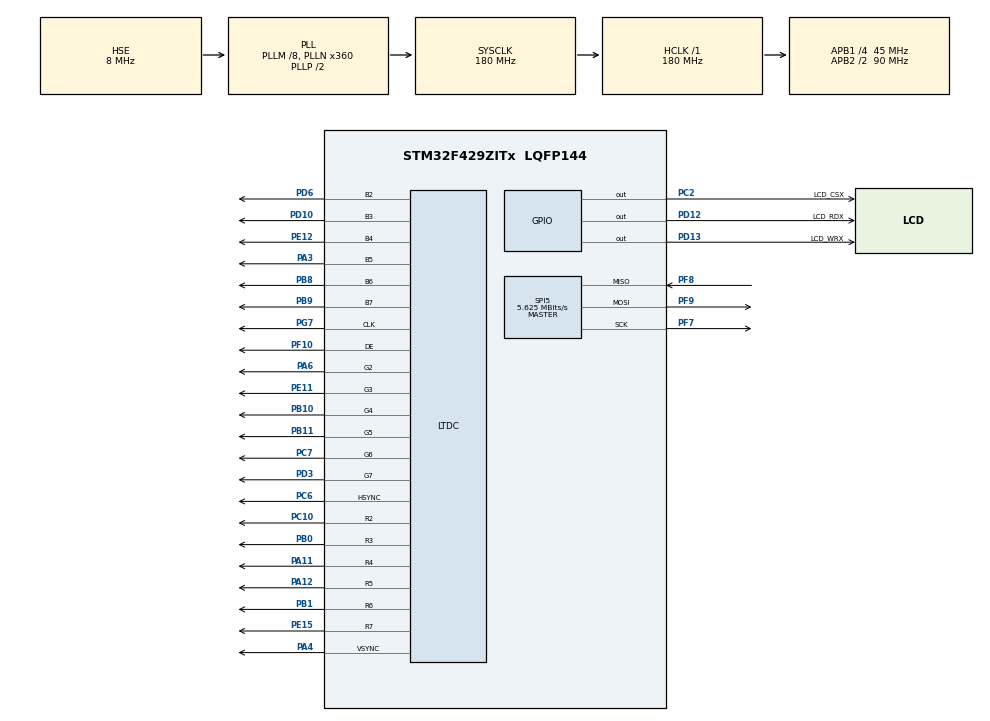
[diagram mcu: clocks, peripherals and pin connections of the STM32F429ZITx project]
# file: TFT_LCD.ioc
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LTDC.ActiveH=320
LTDC.ActiveW=240
LTDC.Alpha_L0=255
LTDC.HBP=20
LTDC.HFP=10
LTDC.HSync=10
LTDC.ImageHeight_L0=320
LTDC.ImageWidth_L0=240
LTDC.Layers=0
LTDC.PixelFormat_L0=LTDC_PIXEL_FORMAT_RGB888
LTDC.VFP=4
LTDC.VSync=2
LTDC.WindowX1_L0=240
LTDC.WindowY1_L0=320
Mcu.Family=STM32F4
Mcu.Name=STM32F429ZITx
Mcu.Package=LQFP144
NVIC.PriorityGroup=NVIC_PRIORITYGROUP_4
PA11.GPIO_Speed=GPIO_SPEED_FREQ_HIGH
PA11.Mode=RGB666
PA11.Signal=LTDC_R4
PA12.GPIO_Speed=GPIO_SPEED_FREQ_HIGH
PA12.Mode=RGB666
PA12.Signal=LTDC_R5
PA13.Mode=Serial_Wire
PA13.Signal=SYS_JTMS-SWDIO
PA14.Mode=Serial_Wire
PA14.Signal=SYS_JTCK-SWCLK
PA3.GPIO_Speed=GPIO_SPEED_FREQ_HIGH
PA3.Mode=RGB666
PA3.Signal=LTDC_B5
PA4.GPIO_Speed=GPIO_SPEED_FREQ_HIGH
PA4.Mode=RGB666
PA4.Signal=LTDC_VSYNC
PA6.GPIO_Speed=GPIO_SPEED_FREQ_HIGH
PA6.Mode=RGB666
PA6.Signal=LTDC_G2
PB0.Mode=RGB666
PB0.Signal=LTDC_R3
PB1.Mode=RGB666
PB1.Signal=LTDC_R6
PB10.Mode=RGB666
PB10.Signal=LTDC_G4
PB11.Mode=RGB666
PB11.Signal=LTDC_G5
PB8.Mode=RGB666
PB8.Signal=LTDC_B6
PB9.Mode=RGB666
PB9.Signal=LTDC_B7
PC10.Mode=RGB666
PC10.Signal=LTDC_R2
PC2.GPIO_Label=LCD_CSX
PC2.GPIO_Speed=GPIO_SPEED_FREQ_HIGH
PC2.Signal=GPIO_Output
PC6.Mode=RGB666
PC6.Signal=LTDC_HSYNC
PC7.Mode=RGB666
PC7.Signal=LTDC_G6
PD10.Mode=RGB666
PD10.Signal=LTDC_B3
PD12.GPIO_Label=LCD_RDX
PD12.GPIO_Speed=GPIO_SPEED_FREQ_HIGH
PD12.Signal=GPIO_Output
PD13.GPIO_Label=LCD_WRX
PD13.GPIO_Speed=GPIO_SPEED_FREQ_HIGH
PD13.Signal=GPIO_Output
PD3.Mode=RGB666
PD3.Signal=LTDC_G7
PD6.Mode=RGB666
PD6.Signal=LTDC_B2
PE11.Mode=RGB666
PE11.Signal=LTDC_G3
PE12.Mode=RGB666
PE12.Signal=LTDC_B4
PE15.Mode=RGB666
PE15.Signal=LTDC_R7
PF10.Mode=RGB666
PF10.Signal=LTDC_DE
PF7.GPIO_PuPd=GPIO_PULLDOWN
PF7.GPIO_Speed=GPIO_SPEED_FREQ_MEDIUM
PF7.Mode=Full_Duplex_Master
PF7.Signal=SPI5_SCK
PF8.GPIO_PuPd=GPIO_PULLDOWN
PF8.GPIO_Speed=GPIO_SPEED_FREQ_MEDIUM
PF8.Mode=Full_Duplex_Master
PF8.Signal=SPI5_MISO
PF9.GPIO_PuPd=GPIO_PULLDOWN
PF9.GPIO_Speed=GPIO_SPEED_FREQ_MEDIUM
PF9.Mode=Full_Duplex_Master
PF9.Signal=SPI5_MOSI
PG7.Mode=RGB666
PG7.Signal=LTDC_CLK
PH0/OSC_IN.Mode=HSE-External-Oscillator
PH0/OSC_IN.Signal=RCC_OSC_IN
PH1/OSC_OUT.Mode=HSE-External-Oscillator
PH1/OSC_OUT.Signal=RCC_OSC_OUT
ProjectManager.HeapSize=0x200
ProjectManager.StackSize=0x400
ProjectManager.TargetToolchain=Makefile
RCC.48MHZClocksFreq_Value=90000000
RCC.AHBFreq_Value=180000000
RCC.APB1CLKDivider=RCC_HCLK_DIV4
RCC.APB1Freq_Value=45000000
RCC.APB1TimFreq_Value=90000000
RCC.APB2CLKDivider=RCC_HCLK_DIV2
RCC.APB2Freq_Value=90000000
RCC.APB2TimFreq_Value=180000000
RCC.CortexFreq_Value=180000000
RCC.HCLKFreq_Value=180000000
RCC.HSE_VALUE=8000000
RCC.HSI_VALUE=16000000
RCC.LSE_VALUE=32768
RCC.PLLM=8
RCC.PLLN=360
RCC.PLLSAIDivR=RCC_PLLSAIDIVR_8
RCC.PLLSAIN=192
RCC.PLLSAIR=4
RCC.PLLSourceVirtual=RCC_PLLSOURCE_HSE
RCC.SYSCLKFreq_VALUE=180000000
RCC.SYSCLKSource=RCC_SYSCLKSOURCE_PLLCLK
RCC.VCOOutputFreq_Value=360000000
SPI5.BaudRatePrescaler=SPI_BAUDRATEPRESCALER_16
SPI5.CalculateBaudRate=5.625 MBits/s
SPI5.Direction=SPI_DIRECTION_2LINES
SPI5.Mode=SPI_MODE_MASTER
SPI5.VirtualType=VM_MASTER
board=custom

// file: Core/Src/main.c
/* USER CODE BEGIN Header */
/**
  ******************************************************************************
  * @file           : main.c
  * @brief          : Main program body
  ******************************************************************************
  * @attention
  *
  * Copyright (c) 2022 STMicroelectronics.
  * All rights reserved.
  *
  * This software is licensed under terms that can be found in the LICENSE file
  * in the root directory of this software component.
  * If no LICENSE file comes with this software, it is provided AS-IS.
  *
  ******************************************************************************
  */
/* USER CODE END Header */
#include "main.h"
#include "ltdc.h"
#include "spi.h"
#include "gpio.h"

void SystemClock_Config(void);

int main(void)
{

  /* MCU Configuration--------------------------------------------------------*/

  /* Reset of all peripherals, Initializes the Flash interface and the Systick. */
  HAL_Init();

  /* Configure the system clock */
  SystemClock_Config();

  /* Initialize all configured peripherals */
  MX_GPIO_Init();
  MX_SPI5_Init();
  /* USER CODE BEGIN 2 */
  LCD_Config();
  /* USER CODE END 2 */

  /* Infinite loop */
  /* USER CODE BEGIN WHILE */

  string_conf.backcolor = 0x0000;
  string_conf.textcolor = 0xFF00;
  string_conf.font = &Font24;

  //LCD_draw_rectangle(20,20,100,100,0xff00);

  LCD_draw_string("HELLO WORLD",20,25,11,&string_conf);

  LCD_draw_string("TETRADYNE",20,50,9,&string_conf);

  LCD_draw_string("20220920",20,75,8,&string_conf);

  while (1)
  {
    /* USER CODE END WHILE */

  }
}

void SystemClock_Config(void)
{
  RCC_OscInitTypeDef RCC_OscInitStruct = {0};
  RCC_ClkInitTypeDef RCC_ClkInitStruct = {0};

  /** Configure the main internal regulator output voltage
  */
  __HAL_RCC_PWR_CLK_ENABLE();
  __HAL_PWR_VOLTAGESCALING_CONFIG(PWR_REGULATOR_VOLTAGE_SCALE1);

  /** Initializes the RCC Oscillators according to the specified parameters
  * in the RCC_OscInitTypeDef structure.
  */
  RCC_OscInitStruct.OscillatorType = RCC_OSCILLATORTYPE_HSE;
  RCC_OscInitStruct.HSEState = RCC_HSE_ON;
  RCC_OscInitStruct.PLL.PLLState = RCC_PLL_ON;
  RCC_OscInitStruct.PLL.PLLSource = RCC_PLLSOURCE_HSE;
  RCC_OscInitStruct.PLL.PLLM = 8;
  RCC_OscInitStruct.PLL.PLLN = 360;
  RCC_OscInitStruct.PLL.PLLP = RCC_PLLP_DIV2;
  RCC_OscInitStruct.PLL.PLLQ = 4;
  if (HAL_RCC_OscConfig(&RCC_OscInitStruct) != HAL_OK)
  {
    Error_Handler();
  }

  /** Activate the Over-Drive mode
  */
  if (HAL_PWREx_EnableOverDrive() != HAL_OK)
  {
    Error_Handler();
  }

  /** Initializes the CPU, AHB and APB buses clocks
  */
  RCC_ClkInitStruct.ClockType = RCC_CLOCKTYPE_HCLK|RCC_CLOCKTYPE_SYSCLK
                              |RCC_CLOCKTYPE_PCLK1|RCC_CLOCKTYPE_PCLK2;
  RCC_ClkInitStruct.SYSCLKSource = RCC_SYSCLKSOURCE_PLLCLK;
  RCC_ClkInitStruct.AHBCLKDivider = RCC_SYSCLK_DIV1;
  RCC_ClkInitStruct.APB1CLKDivider = RCC_HCLK_DIV4;
  RCC_ClkInitStruct.APB2CLKDivider = RCC_HCLK_DIV2;

  if (HAL_RCC_ClockConfig(&RCC_ClkInitStruct, FLASH_LATENCY_5) != HAL_OK)
  {
    Error_Handler();
  }
}

void Error_Handler(void)
{
  __disable_irq();
  while (1)
  {
  }
}
